# S32K322_M7 register map
Vendor: NXP Semiconductors; File version: 1.0
CPU: CM7 r0p1, little endian, MPU, FPU, VTOR, 4 interrupt priority bits
Registers are 32-bit, read-write, reset 0x0 unless marked. A register's access mark holds for its fields unless they carry their own. Offsets are from the block's base; [hi:lo] are bit positions; {n}, {i} and the like mark numbered series; 'fields as' and 'values as' point back to an identical list.

## MSCM
Base 0x40260000
0x00 CPXTYPE ro reset not defined — Processor X Type
  [31:0] PERSONALITY — Personality of CPx
0x04 CPXNUM ro reset not defined — Processor X Number
  [1:0] CPN — Processor Number
    0=Cortex-M7 core 0; 1=Cortex-M7 core 1
0x08 CPXREV ro (reset mask 0xFFFFFF00) — Processor X Revision
  [7:0] RYPZ — Processor Revision
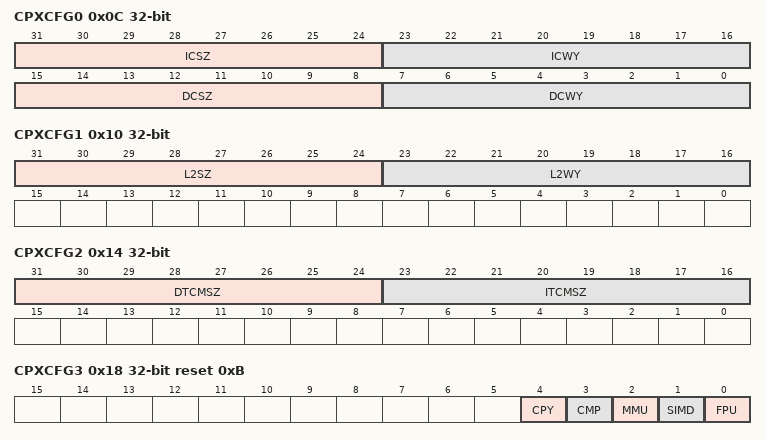
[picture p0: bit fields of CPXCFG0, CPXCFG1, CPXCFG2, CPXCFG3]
0x0C CPXCFG0 ro reset not defined — Processor X Configuration 0
  [31:24] ICSZ — Level 1 Instruction Cache Size
  [23:16] ICWY — L1 Instruction Cache Ways
  [15:8] DCSZ — L1 Data Cache Size
  [7:0] DCWY — L1 Data Cache Ways
0x10 CPXCFG1 ro (reset mask 0xFFFF) — Processor X Configuration 1
  [31:24] L2SZ — L2 Cache Size
  [23:16] L2WY — L2 Cache Ways
0x14 CPXCFG2 ro (reset mask 0xFFFF) — Processor X Configuration 2
  [31:24] DTCMSZ — Tightly Coupled Data Memory Size
  [23:16] ITCMSZ — Instruction Tightly Coupled Memory Size
0x18 CPXCFG3 ro reset 0xB — Processor x Configuration 3
  [4] CPY — Cryptography
    0=Not supported; 1=Supported
  [3] CMP — Core Memory Protection Unit
    0=Not included; 1=Included
  [2] MMU — Memory Management Unit
    0=Not supported; 1=Supported
  [1] SIMD — SIMD/NEON Instruction Support
    0=Not included; 1=Included
  [0] FPU — Floating Point Unit
    0=Not provided; 1=Provided
0x20 CP0TYPE ro reset 0x434D3730 — Processor 0 Type
  [31:0] PERSONALITY — Processor Personality
0x24 CP0NUM ro (reset mask 0xFFFFFFFC) — Processor 0 Number
  [1:0] CPN — Processor Number
0x28 CP0REV ro (reset mask 0xFFFFFF00) — Processor 0 Count
  [7:0] RYPZ — Processor Revision
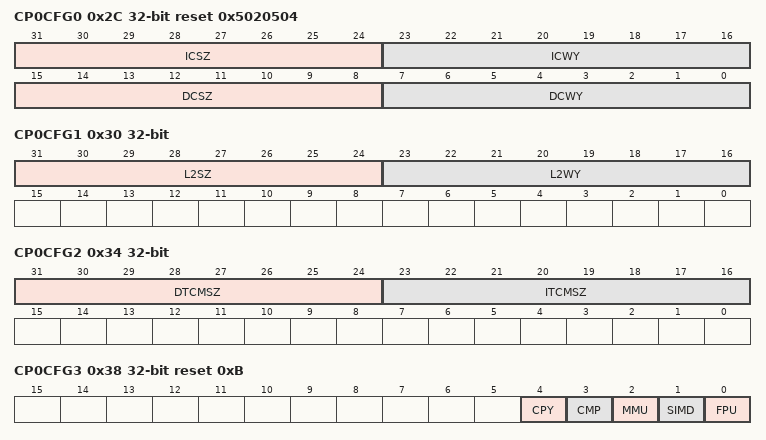
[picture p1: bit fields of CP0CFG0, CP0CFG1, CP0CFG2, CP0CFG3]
0x2C CP0CFG0 ro reset 0x5020504 — Processor 0 Configuration 0
  fields as CPXCFG0
0x30 CP0CFG1 ro — Processor 0 Configuration 1
  [31:24] L2SZ — L2 Cache Size
  [23:16] L2WY — L2 Cache Ways
0x34 CP0CFG2 ro (reset mask 0xFFFF) — Processor 0 Configuration 2
  fields as CPXCFG2
0x38 CP0CFG3 ro reset 0xB — Processor 0 Configuration 3
  fields as CPXCFG3
0x40 CP1TYPE ro reset 0x434D3731 — Processor 1 Type
  [31:0] PERSONALITY — Personality Processor
0x44 CP1NUM ro reset 0x1 — Processor 1 Number
  [1:0] CPN — Processor Number
0x48 CP1REV ro (reset mask 0xFFFFFF00) — Processor 1 Count
  [7:0] RYPZ — Processor Revision
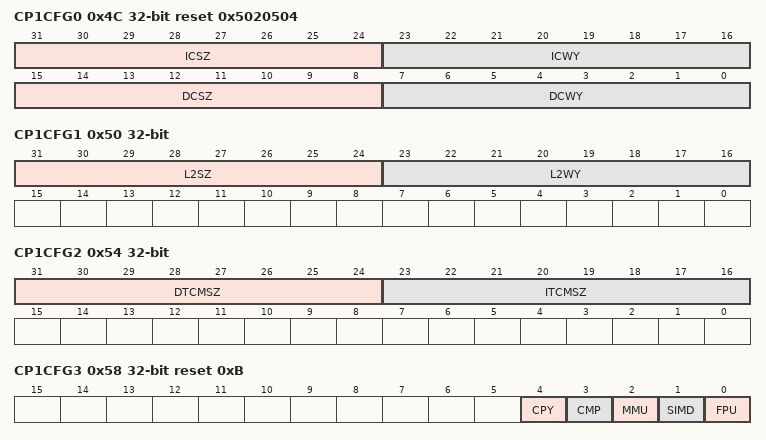
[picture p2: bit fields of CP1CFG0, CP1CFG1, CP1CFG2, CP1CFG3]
0x4C CP1CFG0 ro reset 0x5020504 — Processor 1 Configuration 0
  [31:24] ICSZ — Level 1 Instruction Cache Size
  [23:16] ICWY — Level 1 Instruction Cache Ways
  [15:8] DCSZ — L1 Data Cache Size
  [7:0] DCWY — L1 Data Cache Ways
0x50 CP1CFG1 ro (reset mask 0xFFFF) — Processor 1 Configuration 1
  [31:24] L2SZ — L2 Cache Size
  [23:16] L2WY — L2 Cache Ways
0x54 CP1CFG2 ro (reset mask 0xFFFF) — Processor 1 Configuration 2
  fields as CPXCFG2
0x58 CP1CFG3 ro reset 0xB — Processor 1 Configuration 3
  [4] CPY — Cryptography
    0=Not supported; 1=Supported
  [3] CMP — Core Memory Protection Unit
    0=Not included; 1=Included
  [2] MMU — Memory Management Unit
    0=Not supported; 1=Supported
  [1] SIMD — SIMD/NEON Instruction Support
    0=Not included; 1=Included
  [0] FPU — Floating Point Unit
    0=Not included; 1=Included
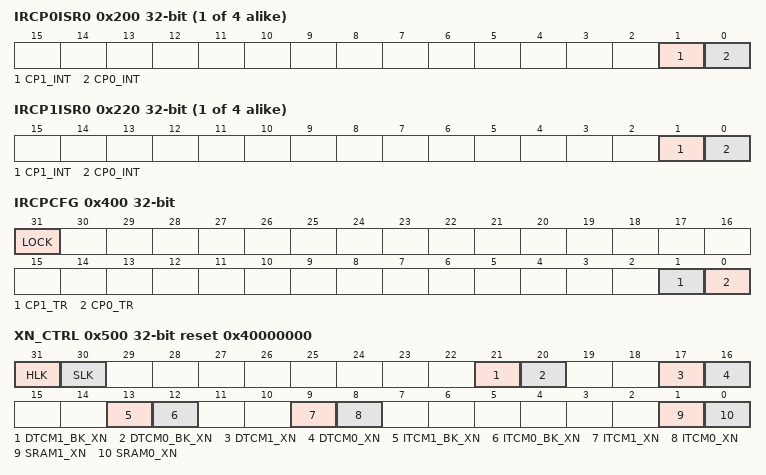
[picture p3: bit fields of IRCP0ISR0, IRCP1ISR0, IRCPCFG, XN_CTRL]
{0x200+8i} IRCP0ISR{i} write-1-clears (i=0..3) — Interrupt Router CP0 Interrupt Status
  [1] CP1_INT write-1-clears — CP1-to-CPn Interrupt
    0=No interrupt is asserted to CPn; 1=Interrupt to CPn is asserted
  [0] CP0_INT write-1-clears — CP0-to-CPn Interrupt
    0=No interrupt asserted to CPn; 1=Interrupt to CPn asserted
{0x204+8i} IRCP0IGR{i} (i=0..3) — Interrupt Router CP0 Interrupt Generation
  [0] INT_EN — Interrupt Enable
{0x220+8i} IRCP1ISR{i} write-1-clears (i=0..3) — Interrupt Router CP1 Interrupt Status
  fields as IRCP0ISR0
{0x224+8i} IRCP1IGR{i} (i=0..3) — Interrupt Router CP1 Interrupt Generation
  [0] INT_EN — Interrupt Enable
0x400 IRCPCFG — Interrupt Router Configuration
  [31] LOCK
    0=Register can be written by any privileged write; 1=Register is locked (read-only) until the next reset
  [1] CP1_TR — CP1 as Trusted Core
    0=Not trusted; 1=Trusted
  [0] CP0_TR — CP0 as Trusted Core
    0=Not trusted; 1=Trusted
0x500 XN_CTRL reset 0x40000000 — Memory Execution Control
  [31] HLK — Hard Lock
    0=Disabled; 1=Enabled
  [30] SLK — Soft Lock
    0=Disabled; 1=Enabled
  [21] DTCM1_BK_XN — DTCM Core 1 Backdoor Access Execution Control
    0=Allowed; 1=Disabled
  [20] DTCM0_BK_XN — DTCM Core 0 Backdoor Access Execution Control
    0=Allowed; 1=Disabled
  [17] DTCM1_XN — DTCM Core 1 Direct Access Execution Control
    0=Allowed; 1=Disabled
  [16] DTCM0_XN — DTCM Core 0 Direct Access Execution Control
    0=Allowed; 1=Disabled
  [13] ITCM1_BK_XN — ITCM Core 1 Backdoor Access Execution Control
    0=Allowed; 1=Disabled
  [12] ITCM0_BK_XN — ITCM Core 0 Backdoor Access Execution Control
    0=Allowed; 1=Disabled
  [9] ITCM1_XN — ITCM Core 1 Direct Access Execution Control
    0=Allowed; 1=Disabled
  [8] ITCM0_XN — ITCM Core 0 Direct Access Execution Control
    0=Allowed; 1=Disabled
  [1] SRAM1_XN — SRAM 1 Controller Access Execution Control
    0=Allowed; 1=Not allowed
  [0] SRAM0_XN — SRAM 0 Controller Access Execution Control
    0=Allowed; 1=Not allowed
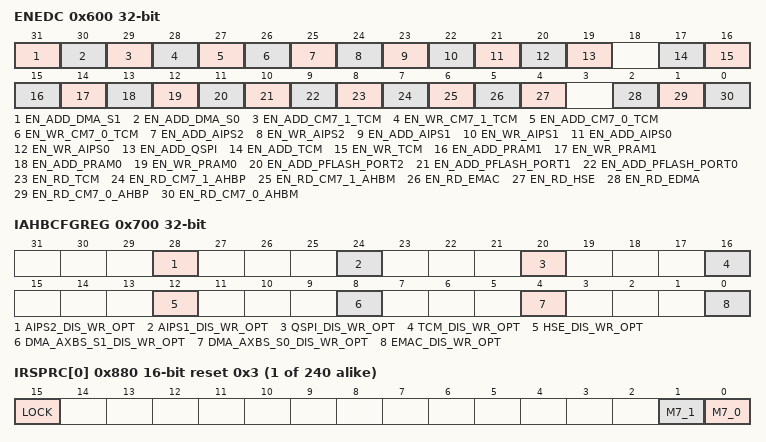
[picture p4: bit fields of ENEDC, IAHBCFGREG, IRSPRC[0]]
0x600 ENEDC — Enable Interconnect Error Detection
  [all] fields
    0=Disabled; 1=Enabled
  [31] EN_ADD_DMA_S1 — Enable DMA AXBS S1 Port
  [30] EN_ADD_DMA_S0 — Enable DMA AXBS S0 Port
  [29] EN_ADD_CM7_1_TCM — Enable Address Check Cortex-M7_1_TCM
  [28] EN_WR_CM7_1_TCM — Enable Write Data Check Cortex-M7_1_TCM
  [27] EN_ADD_CM7_0_TCM — Enable Address Check Cortex-M7_0_TCM
  [26] EN_WR_CM7_0_TCM — Enable Write Data Check Cortex-M7_0_TCM
  [25] EN_ADD_AIPS2 — Enable Address Check AIPS2
  [24] EN_WR_AIPS2 — Enable Write Data Check AIPS2
  [23] EN_ADD_AIPS1 — Enable Address Check AIPS1
  [22] EN_WR_AIPS1 — Enable Write Data Check AIPS1
  [21] EN_ADD_AIPS0 — Enable Address Check AIPS0
  [20] EN_WR_AIPS0 — Enable Write Data Check AIPS0
  [19] EN_ADD_QSPI — Enable Address Check QuadSPI
  [17] EN_ADD_TCM — Enable Address Check TCM
  [16] EN_WR_TCM — Enable Write Data Check TCM
  [15] EN_ADD_PRAM1 — Enable Address Check PRAM1
  [14] EN_WR_PRAM1 — Enable Write Data Check PRAM1
  [13] EN_ADD_PRAM0 — Enable Address Check PRAM0
  [12] EN_WR_PRAM0 — Enable Write Data Check PRAM0
  [11] EN_ADD_PFLASH_PORT2 — Enable Address Check P_FLASH_PORT2
  [10] EN_ADD_PFLASH_PORT1 — Enable Address Check P_FLASH_PORT1
  [9] EN_ADD_PFLASH_PORT0 — Enable Address Check P_FLASH_PORT0
  [8] EN_RD_TCM — Enable Read Data Check TCM
  [7] EN_RD_CM7_1_AHBP — Enable Read Data Check Cortex-M7_1_AHBP
  [6] EN_RD_CM7_1_AHBM — Enable Read Data Check Cortex-M7_1_AHBM
  [5] EN_RD_EMAC — Enable Read Data Check EMAC
  [4] EN_RD_HSE — Enable Read Data Check HSE
  [2] EN_RD_EDMA — Enable Read Data Check eDMA
  [1] EN_RD_CM7_0_AHBP — Enable Read Data Check Cortex-M7_0_AHBP
  [0] EN_RD_CM7_0_AHBM — Enable Read Data Check Cortex-M7_0_AHBM
0x700 IAHBCFGREG — AHB Gasket Configuration
  [all] fields
    0=Enabled; 1=Disabled
  [28] AIPS2_DIS_WR_OPT — Determines whether write burst optimizations in the AIPS2 AHB gasket are enabled or disabled
  [24] AIPS1_DIS_WR_OPT — Determines whether write burst optimizations in the AIPS1 AHB gasket are enabled or disabled
  [20] QSPI_DIS_WR_OPT — Determines whether write burst optimizations in the QuadSPI AHB gasket are enabled or disabled
  [16] TCM_DIS_WR_OPT — Determines whether write burst optimizations in the TCM AHB gasket are enabled or disabled
  [12] HSE_DIS_WR_OPT — Determines whether write burst optimizations in the HSE AHB gasket are enabled or disabled
  [8] DMA_AXBS_S1_DIS_WR_OPT — Determines whether write burst optimizations in the DMA AXBS S1 AHB gasket are enabled or disabled
  [4] DMA_AXBS_S0_DIS_WR_OPT — Determines whether write burst optimizations in the DMA AXBS S0 AHB gasket are enabled or disabled
  [0] EMAC_DIS_WR_OPT — Determines whether write burst optimizations in the EMAC AHB gasket are enabled or disabled
{0x880+2i} IRSPRC[{i}] (i=0..239) 16-bit reset 0x3 — Interrupt Router Shared Peripheral Routing Control
  [15] LOCK
    0=Writes to IRSPRCn allowed; 1=Writes to IRSPRCn ignored
  [1] M7_1 — Enable Cortex-M7_1 Interrupt Steering
    0=Routing disabled; 1=Routing enabled
  [0] M7_0 — Enable Cortex-M7_0 Interrupt Steering
    0=Routing disabled; 1=Routing enabled
